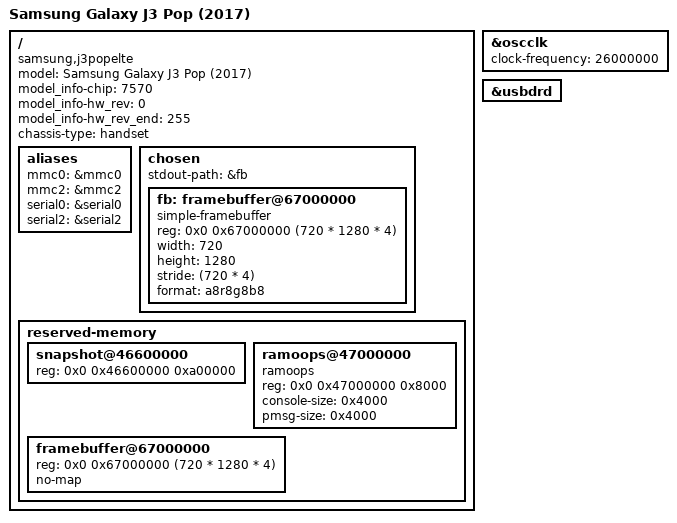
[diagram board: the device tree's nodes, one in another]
// SPDX-License-Identifier: GPL-2.0
/*
 * Samsung Galaxy J3 Pop (2017) (j3popelte) device tree source
 *
 * Copyright (c) 2024 Andras Sebok <sebokandris2009@gmail.com>
 * Copyright (c) 2026 SED4906 <sed4906birdie@gmail.com>
 */

/dts-v1/;
#include "exynos7570.dtsi"
#include <dt-bindings/gpio/gpio.h>
#include <dt-bindings/input/input.h>
#include <dt-bindings/interrupt-controller/irq.h>

/ {
	model = "Samsung Galaxy J3 Pop (2017)";
	model_info-chip = <7570>;
	model_info-hw_rev = <0>;
	model_info-hw_rev_end = <255>;
	compatible = "samsung,j3popelte", "samsung,exynos7570", "samsung,exynos7870";
	chassis-type = "handset";

	aliases {
		mmc0 = &mmc0;
		mmc2 = &mmc2;
		serial0 = &serial0;
		serial2 = &serial2;
	};

	chosen {
		#address-cells = <2>;
		#size-cells = <1>;
		ranges;

		stdout-path = &fb;

		fb: framebuffer@67000000 {
			compatible = "simple-framebuffer";
			reg = <0x0 0x67000000 (720 * 1280 * 4)>;
			width = <720>;
			height = <1280>;
			stride = <(720 * 4)>;
			format = "a8r8g8b8";
		};
	};

	reserved-memory {
		#address-cells = <2>;
		#size-cells = <1>;
		ranges;

		snapshot@46600000 {
			reg = <0x0 0x46600000 0xa00000>;
		};

		ramoops@47000000 {
			compatible = "ramoops";
			reg = <0x0 0x47000000 0x8000>;
			console-size = <0x4000>;
			pmsg-size = <0x4000>;
		};

		framebuffer@67000000 {
			reg = <0x0 0x67000000 (720 * 1280 * 4)>;
			no-map;
		};
	};
};

&oscclk {
	clock-frequency = <26000000>;
};

&usbdrd {
	status = "okay";
};
